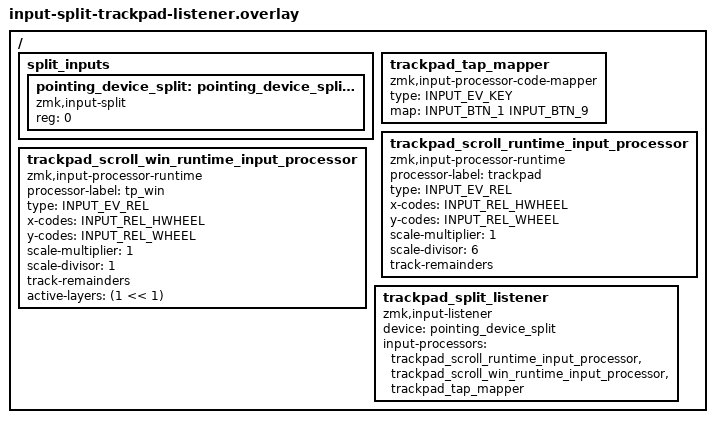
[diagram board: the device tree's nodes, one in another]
#include <dt-bindings/zmk/runtime_input_processor.h>
#include <zephyr/dt-bindings/input/input-event-codes.h>

/*
 * 左ペリフェラルの mini トラックパッド (input-trackpad-mini + input-split) を
 * セントラルで受ける。ドライバが scroller-mode でホイールとボタンを直接出すので、
 * ここではスクロール量とタップのボタンだけを調整する。
 * スクロール量は DYA Studio の Trackball タブ ("trackpad") から実行時に変えられる。
 * input-split-listener と同じノードを定義するため、同時に指定しないこと。
 */
/ {
    split_inputs {
        #address-cells = <1>;
        #size-cells = <0>;

        pointing_device_split: pointing_device_split@0 {
            compatible = "zmk,input-split";
            reg = <0>;
        };
    };

    /*
     * ドライバは 1 本指タップを BTN_0、2 本指タップを BTN_1 で出す。
     * input listener は BTN_0〜4 以外を捨てるので、BTN_9 へ付け替えると無効になる。
     */
    trackpad_tap_mapper: trackpad_tap_mapper {
        compatible = "zmk,input-processor-code-mapper";
        #input-processor-cells = <0>;
        type = <INPUT_EV_KEY>;
        /* 1 本指タップ (BTN_0) はそのまま左クリック */
        map = <INPUT_BTN_1 INPUT_BTN_9>;  /* 2 本指タップ → 無効 */
    };

    /*
     * ドライバはタッチ座標の差分 (縦の解像度 300) をそのままホイール量として出す。
     * 1/3 でも速すぎたので初期値は 1/6。DYA Studio から実行時に変えられる。
     */
    trackpad_scroll_runtime_input_processor: trackpad_scroll_runtime_input_processor {
        compatible = "zmk,input-processor-runtime";
        processor-label = "trackpad";
        type = <INPUT_EV_REL>;
        x-codes = <INPUT_REL_HWHEEL>;
        y-codes = <INPUT_REL_WHEEL>;
        scale-multiplier = <1>;
        scale-divisor = <6>;
        track-remainders;
        #input-processor-cells = <0>;
    };

    /*
     * WIN レイヤー (keymap.keymap の LT_WIN = 1) がオンのときだけ、上の "trackpad" の
     * 後にさらに掛ける倍率。BT1/BT2 に切り替えるとオンになるので、Windows 側の
     * スクロール量だけを DYA Studio の "tp_win" で調整できる。初期値は等倍 (変化なし)。
     */
    trackpad_scroll_win_runtime_input_processor: trackpad_scroll_win_runtime_input_processor {
        compatible = "zmk,input-processor-runtime";
        processor-label = "tp_win";
        type = <INPUT_EV_REL>;
        x-codes = <INPUT_REL_HWHEEL>;
        y-codes = <INPUT_REL_WHEEL>;
        scale-multiplier = <1>;
        scale-divisor = <1>;
        track-remainders;
        active-layers = <(1 << 1)>;
        #input-processor-cells = <0>;
    };

    trackpad_split_listener: trackpad_split_listener {
        compatible = "zmk,input-listener";
        device = <&pointing_device_split>;
        /* スクロール量 (慣性分も含む) を縮め、タップのボタンを付け替える */
        input-processors = <&trackpad_scroll_runtime_input_processor>,
                           <&trackpad_scroll_win_runtime_input_processor>,
                           <&trackpad_tap_mapper>;
    };
};
